# nrf5340_application register map
Vendor: Nordic Semiconductor; Series: nrf53; File version: 1
CPU: CM33 r0p4, little endian, MPU, FPU, 3 interrupt priority bits, 69 interrupts
Registers are 32-bit, read-write, reset 0x0 unless marked. A register's access mark holds for its fields unless they carry their own. Offsets are from the block's base; [hi:lo] are bit positions; lines under a group give offsets from that group; {n}, {i} and the like mark numbered series.

## FICR_S — Factory Information Configuration Registers
Base 0x00FF0000
0x200 INFO group — Device info
  0x00 CONFIGID ro reset 0xFFFFFFFF — Configuration identifier
    [15:0] HWID — Identification number for the HW
  {0x4+4j} DEVICEID[{j}] (j=0..1) ro reset 0xFFFFFFFF — Description collection: Device identifier
    [31:0] DEVICEID — 64 bit unique device identifier
  0x0C PART ro reset 0x5340 — Part code
    [31:0] PART
      0x5340=N5340 (nRF5340); 0xFFFFFFFF=Unspecified
  0x10 VARIANT ro reset 0xFFFFFFFF — Part Variant, Hardware version and Production configuration
    [31:0] VARIANT — Part Variant, Hardware version and Production configuration, encoded as ASCII
      0x514B4141=QKAA; 0x434C4141=CLAA; 0xFFFFFFFF=Unspecified
  0x14 PACKAGE ro reset 0xFFFFFFFF — Package option
    [31:0] PACKAGE
      0x2000=QK (QKxx - 94-pin aQFN); 0x2005=CL (CLxx - WLCSP); 0xFFFFFFFF=Unspecified
  0x18 RAM ro reset 0xFFFFFFFF — RAM variant
    [31:0] RAM
      16=K16 (16 kByte RAM); 32=K32 (32 kByte RAM); 64=K64 (64 kByte RAM); 128=K128 (128 kByte RAM); 0x100=K256 (256 kByte RAM); 0x200=K512 (512 kByte RAM); 0xFFFFFFFF=Unspecified
  0x1C FLASH ro reset 0xFFFFFFFF — Flash variant
    [31:0] FLASH
      128=K128 (128 kByte FLASH); 0x100=K256 (256 kByte FLASH); 0x200=K512 (512 kByte FLASH); 0x400=K1024 (1 MByte FLASH); 0x800=K2048 (2 MByte FLASH); 0xFFFFFFFF=Unspecified
  0x20 CODEPAGESIZE ro reset 0x1000 — Code memory page size in bytes
    [31:0] CODEPAGESIZE
      0x1000=K4096 (4 kByte)
  0x24 CODESIZE ro reset 0x100 — Code memory size
    [31:0] CODESIZE — Code memory size in number of pages
      0x100=P256 (256 pages)
  0x28 DEVICETYPE ro
    [31:0] DEVICETYPE
      0=Die (Device is an physical DIE); 0xFFFFFFFF=FPGA (Device is an FPGA)
{0x300+8i} TRIMCNF[{i}] (i=0..31) group — Unspecified
  0x00 ADDR ro reset 0xFFFFFFFF — Description cluster: Address of the PAR register which will be written
    [31:0] Address
  0x04 DATA ro reset 0xFFFFFFFF — Description cluster: Data
    [31:0] Data — Data to be written into the PAR register
0x450 NFC group — Unspecified
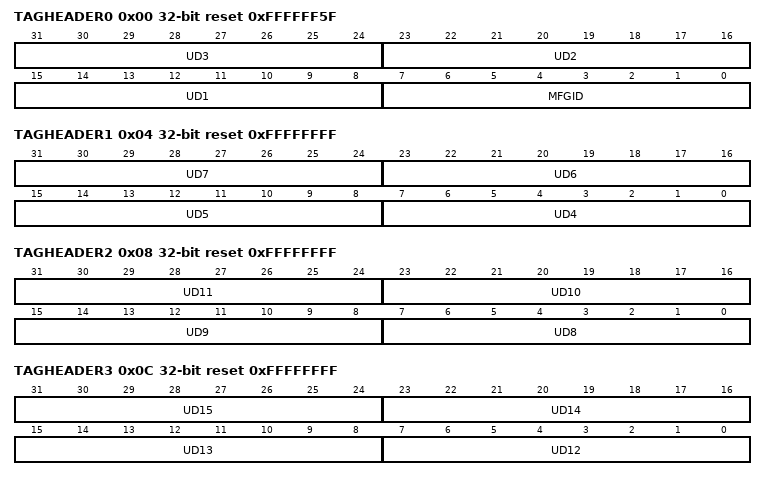
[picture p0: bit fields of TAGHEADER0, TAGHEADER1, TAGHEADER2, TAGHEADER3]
  0x00 TAGHEADER0 ro reset 0xFFFFFF5F — Default header for NFC Tag. Software can read these values to populate NFCID1_3RD_LAST, NFCID1_2ND_LAST and NFCID1_LAST.
    [31:24] UD3 — Unique identifier byte 3
    [23:16] UD2 — Unique identifier byte 2
    [15:8] UD1 — Unique identifier byte 1
    [7:0] MFGID — Default Manufacturer ID: Nordic Semiconductor ASA has ICM 0x5F
  0x04 TAGHEADER1 ro reset 0xFFFFFFFF — Default header for NFC Tag. Software can read these values to populate NFCID1_3RD_LAST, NFCID1_2ND_LAST and NFCID1_LAST.
    [8n-25:8n-32] UD{n} (n=4..7) — Unique identifier byte {n}
  0x08 TAGHEADER2 ro reset 0xFFFFFFFF — Default header for NFC Tag. Software can read these values to populate NFCID1_3RD_LAST, NFCID1_2ND_LAST and NFCID1_LAST.
    [8n-57:8n-64] UD{n} (n=8..11) — Unique identifier byte {n}
  0x0C TAGHEADER3 ro reset 0xFFFFFFFF — Default header for NFC Tag. Software can read these values to populate NFCID1_3RD_LAST, NFCID1_2ND_LAST and NFCID1_LAST.
    [8n-89:8n-96] UD{n} (n=12..15) — Unique identifier byte {n}
0xC00 TRNG90B group — NIST800-90B RNG calibration data
  0x00 BYTES ro reset 0x210 — Amount of bytes for the required entropy bits
  0x04 RCCUTOFF ro reset 0xFFFFFFFF — Repetition counter cutoff
  0x08 APCUTOFF ro reset 0xFFFFFFFF — Adaptive proportion cutoff
  0x0C STARTUP ro reset 0xFFFFFFFF — Amount of bytes for the startup tests
  {0xC+4j} ROSC{j} ro reset 0xFFFFFFFF (j=1..4) — Sample count for ring oscillator {j}
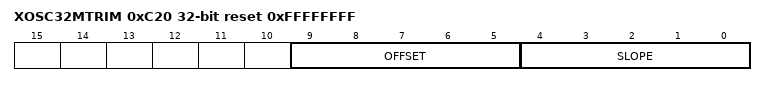
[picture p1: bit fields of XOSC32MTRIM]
0xC20 XOSC32MTRIM ro reset 0xFFFFFFFF — XOSC32M capacitor selection trim values
  [9:5] OFFSET — Offset trim factor on integer form
  [4:0] SLOPE — Slope trim factor on twos complement form

## Notices in the file
Copyright (c) 2010 - 2024, Nordic Semiconductor ASA All rights reserved.
SPDX-License-Identifier: BSD-3-Clause
Redistribution and use in source and binary forms, with or without
modification, are permitted provided that the following conditions are met:
1. Redistributions of source code must retain the above copyright notice, this
list of conditions and the following disclaimer.
2. Redistributions in binary form must reproduce the above copyright
notice, this list of conditions and the following disclaimer in the
documentation and/or other materials provided with the distribution.
3. Neither the name of Nordic Semiconductor ASA nor the names of its
contributors may be used to endorse or promote products derived from this
software without specific prior written permission.
THIS SOFTWARE IS PROVIDED BY THE COPYRIGHT HOLDERS AND CONTRIBUTORS "AS IS"
AND ANY EXPRESS OR IMPLIED WARRANTIES, INCLUDING, BUT NOT LIMITED TO, THE
IMPLIED WARRANTIES OF MERCHANTABILITY, AND FITNESS FOR A PARTICULAR PURPOSE
ARE DISCLAIMED. IN NO EVENT SHALL NORDIC SEMICONDUCTOR ASA OR CONTRIBUTORS BE
LIABLE FOR ANY DIRECT, INDIRECT, INCIDENTAL, SPECIAL, EXEMPLARY, OR
CONSEQUENTIAL DAMAGES (INCLUDING, BUT NOT LIMITED TO, PROCUREMENT OF
SUBSTITUTE GOODS OR SERVICES; LOSS OF USE, DATA, OR PROFITS; OR BUSINESS
INTERRUPTION) HOWEVER CAUSED AND ON ANY THEORY OF LIABILITY, WHETHER IN
CONTRACT, STRICT LIABILITY, OR TORT (INCLUDING NEGLIGENCE OR OTHERWISE)
ARISING IN ANY WAY OUT OF THE USE OF THIS SOFTWARE, EVEN IF ADVISED OF THE
POSSIBILITY OF SUCH DAMAGE.
